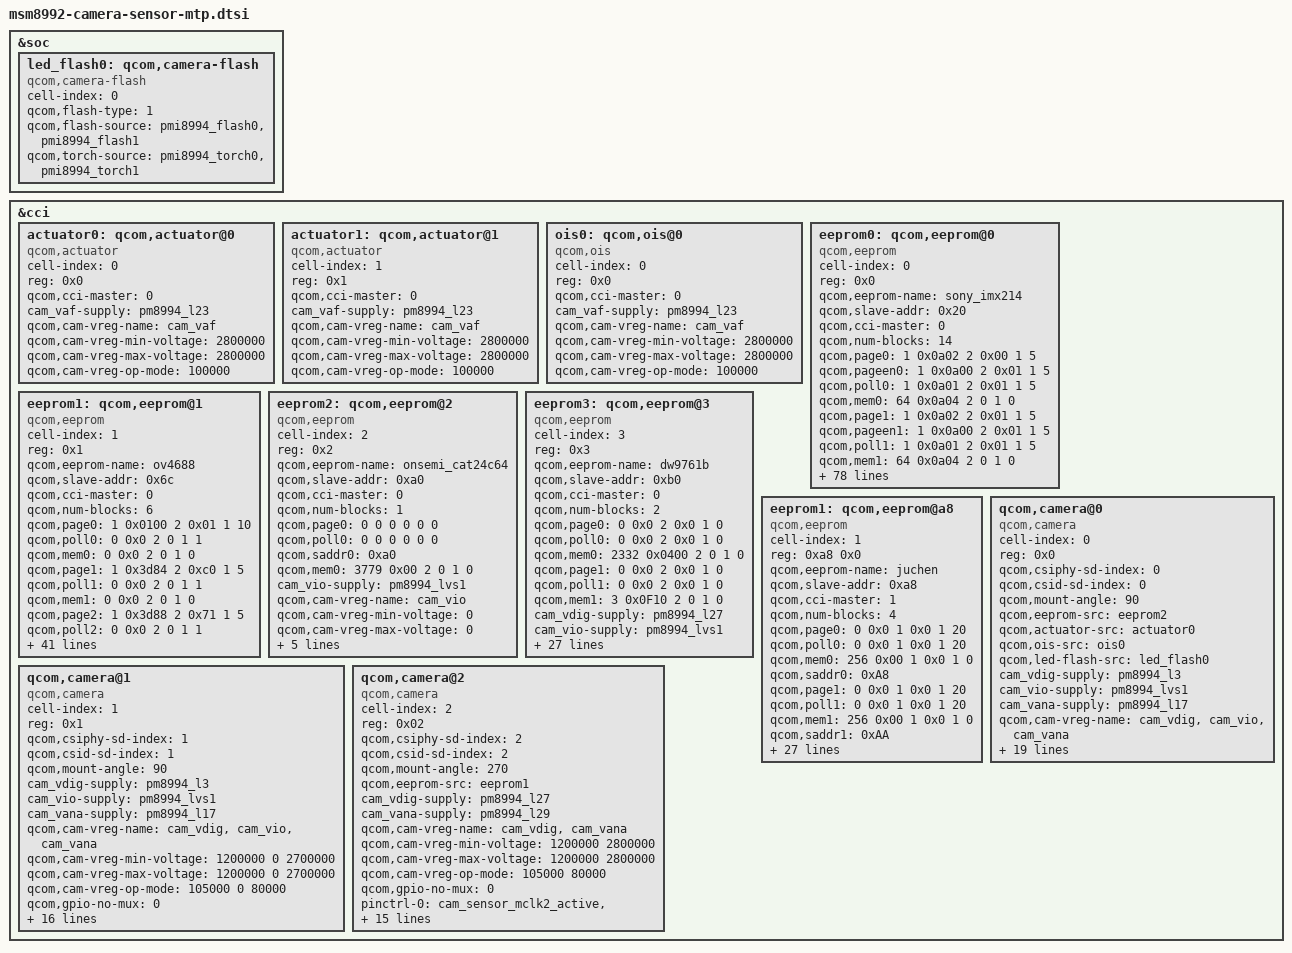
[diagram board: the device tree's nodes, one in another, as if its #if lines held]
/*
 * Copyright (c) 2014-2016, The Linux Foundation. All rights reserved.
 *
 * This program is free software; you can redistribute it and/or modify
 * it under the terms of the GNU General Public License version 2 and
 * only version 2 as published by the Free Software Foundation.
 *
 * This program is distributed in the hope that it will be useful,
 * but WITHOUT ANY WARRANTY; without even the implied warranty of
 * MERCHANTABILITY or FITNESS FOR A PARTICULAR PURPOSE.  See the
 * GNU General Public License for more details.
 */

&soc {
	led_flash0: qcom,camera-flash {
		cell-index = <0>;
		compatible = "qcom,camera-flash";
		qcom,flash-type = <1>;
		qcom,flash-source = <&pmi8994_flash0 &pmi8994_flash1>;
		qcom,torch-source = <&pmi8994_torch0 &pmi8994_torch1>;
	};
};

&cci {
	actuator0: qcom,actuator@0 {
		cell-index = <0>;
		reg = <0x0>;
		compatible = "qcom,actuator";
		qcom,cci-master = <0>;
		cam_vaf-supply = <&pm8994_l23>;
		qcom,cam-vreg-name = "cam_vaf";
		qcom,cam-vreg-min-voltage = <2800000>;
		qcom,cam-vreg-max-voltage = <2800000>;
		qcom,cam-vreg-op-mode = <100000>;
	};

#ifndef CONFIG_VENDOR_EDIT
	actuator1: qcom,actuator@1 {
		cell-index = <1>;
		reg = <0x1>;
		compatible = "qcom,actuator";
		qcom,cci-master = <0>;
		cam_vaf-supply = <&pm8994_l23>;
		qcom,cam-vreg-name = "cam_vaf";
		qcom,cam-vreg-min-voltage = <2800000>;
		qcom,cam-vreg-max-voltage = <2800000>;
		qcom,cam-vreg-op-mode = <100000>;
	};


	ois0: qcom,ois@0 {
		cell-index = <0>;
		reg = <0x0>;
		compatible = "qcom,ois";
		qcom,cci-master = <0>;
		cam_vaf-supply = <&pm8994_l23>;
		qcom,cam-vreg-name = "cam_vaf";
		qcom,cam-vreg-min-voltage = <2800000>;
		qcom,cam-vreg-max-voltage = <2800000>;
		qcom,cam-vreg-op-mode = <100000>;
	};

	eeprom0: qcom,eeprom@0 {
		cell-index = <0>;
		reg = <0x0>;
		qcom,eeprom-name = "sony_imx214";
		compatible = "qcom,eeprom";
		qcom,slave-addr = <0x20>;
		qcom,cci-master = <0>;
		qcom,num-blocks = <14>;
		qcom,page0 = <1 0x0a02 2 0x00 1 5>;
		qcom,pageen0 = <1 0x0a00 2 0x01 1 5>;
		qcom,poll0 = <1 0x0a01 2 0x01 1 5>;
		qcom,mem0 = <64 0x0a04 2 0 1 0>;

		qcom,page1 = <1 0x0a02 2 0x01 1 5>;
		qcom,pageen1 = <1 0x0a00 2 0x01 1 5>;
		qcom,poll1 = <1 0x0a01 2 0x01 1 5>;
		qcom,mem1 = <64 0x0a04 2 0 1 0>;

		qcom,page2 = <1 0x0a02 2 0x02 1 5>;
		qcom,pageen2 = <1 0x0a00 2 0x01 1 5>;
		qcom,poll2 = <1 0x0a01 2 0x01 1 5>;
		qcom,mem2 = <64 0x0a04 2 0 1 0>;

		qcom,page3 = <1 0x0a02 2 0x03 1 5>;
		qcom,pageen3 = <1 0x0a00 2 0x01 1 5>;
		qcom,poll3 = <1 0x0a01 2 0x01 1 5>;
		qcom,mem3 = <64 0x0a04 2 0 1 0>;

		qcom,page4 = <1 0x0a02 2 0x04 1 5>;
		qcom,pageen4 = <1 0x0a00 2 0x01 1 5>;
		qcom,poll4 = <1 0x0a01 2 0x01 1 5>;
		qcom,mem4 = <64 0x0a04 2 0 1 0>;

		qcom,page5 = <1 0x0a02 2 0x05 1 5>;
		qcom,pageen5 = <1 0x0a00 2 0x01 1 5>;
		qcom,poll5 = <1 0x0a01 2 0x01 1 5>;
		qcom,mem5 = <64 0x0a04 2 0 1 0>;

		qcom,page6 = <1 0x0a02 2 0x06 1 5>;
		qcom,pageen6 = <1 0x0a00 2 0x01 1 5>;
		qcom,poll6 = <1 0x0a01 2 0x01 1 5>;
		qcom,mem6 = <64 0x0a04 2 0 1 0>;

		qcom,page7 = <1 0x0a02 2 0x07 1 5>;
		qcom,pageen7 = <1 0x0a00 2 0x01 1 5>;
		qcom,poll7 = <1 0x0a01 2 0x01 1 5>;
		qcom,mem7 = <64 0x0a04 2 0 1 0>;

		qcom,page8 = <1 0x0a02 2 0x08 1 5>;
		qcom,pageen8 = <1 0x0a00 2 0x01 1 5>;
		qcom,poll8 = <1 0x0a01 2 0x01 1 5>;
		qcom,mem8 = <64 0x0a04 2 0 1 0>;

		qcom,page9 = <1 0x0a02 2 0x09 1 5>;
		qcom,pageen9 = <1 0x0a00 2 0x01 1 5>;
		qcom,poll9 = <1 0x0a01 2 0x01 1 5>;
		qcom,mem9 = <64 0x0a04 2 0 1 0>;

		qcom,page10 = <1 0x0a02 2 0x0A 1 5>;
		qcom,pageen10 = <1 0x0a00 2 0x01 1 5>;
		qcom,poll10 = <1 0x0a01 2 0x01 1 5>;
		qcom,mem10 = <64 0x0a04 2 0 1 0>;

		qcom,page11 = <1 0x0a02 2 0x0B 1 5>;
		qcom,pageen11 = <1 0x0a00 2 0x01 1 5>;
		qcom,poll11 = <1 0x0a01 2 0x01 1 5>;
		qcom,mem11 = <64 0x0a04 2 0 1 0>;

		qcom,page12 = <1 0x0a02 2 0x0C 1 5>;
		qcom,pageen12 = <1 0x0a00 2 0x01 1 5>;
		qcom,poll12 = <1 0x0a01 2 0x01 1 5>;
		qcom,mem12 = <64 0x0a04 2 0 1 0>;

		qcom,page13 = <1 0x0a02 2 0x0D 1 5>;
		qcom,pageen13 = <1 0x0a00 2 0x01 1 5>;
		qcom,poll13 = <1 0x0a01 2 0x01 1 5>;
		qcom,mem13 = <64 0x0a04 2 0 1 0>;

		cam_vdig-supply = <&pm8994_l27>;
		cam_vio-supply = <&pm8994_lvs1>;
		cam_vana-supply = <&pm8994_l17>;
		qcom,cam-vreg-name = "cam_vdig", "cam_vio", "cam_vana";
		qcom,cam-vreg-min-voltage = <1050000 0 2700000>;
		qcom,cam-vreg-max-voltage = <1050000 0 2700000>;
		qcom,cam-vreg-op-mode = <105000 0 80000>;
		qcom,gpio-no-mux = <0>;
		pinctrl-names = "cam_default", "cam_suspend";
		pinctrl-0 = <&cam_sensor_mclk0_active &cam_sensor_rear_active>;
		pinctrl-1 = <&cam_sensor_mclk0_suspend &cam_sensor_rear_suspend>;
		gpios = <&msm_gpio 13 0>,
			<&msm_gpio 92 0>,
			<&msm_gpio 91 0>;
		qcom,gpio-reset = <1>;
		qcom,gpio-standby = <2>;
		qcom,gpio-req-tbl-num = <0 1 2>;
		qcom,gpio-req-tbl-flags = <1 0 0>;
		qcom,gpio-req-tbl-label = "CAMIF_MCLK0",
					  "CAM_RESET0",
					  "CAM_STANDBY0";
		qcom,cam-power-seq-type = "sensor_vreg", "sensor_vreg", "sensor_vreg",
			"sensor_gpio", "sensor_gpio" , "sensor_clk";
		qcom,cam-power-seq-val = "cam_vdig", "cam_vana", "cam_vio",
			"sensor_gpio_reset", "sensor_gpio_standby","sensor_cam_mclk";
		qcom,cam-power-seq-cfg-val = <1 1 1 1 1 24000000>;
		qcom,cam-power-seq-delay = <1 1 1 30 30 5>;
		status = "ok";
		clocks = <&clock_mmss clk_mclk0_clk_src>,
				<&clock_mmss clk_camss_mclk0_clk>;
		clock-names = "cam_src_clk", "cam_clk";
	};

	eeprom1: qcom,eeprom@1 {
		cell-index = <1>;
		reg = <0x1>;
		qcom,eeprom-name = "ov4688";
		compatible = "qcom,eeprom";
		qcom,slave-addr = <0x6c>;
		qcom,cci-master = <0>;
		qcom,num-blocks = <6>;
		qcom,page0 = <1 0x0100 2 0x01 1 10>;
		qcom,poll0 = <0 0x0 2 0 1 1>;
		qcom,mem0 = <0 0x0 2 0 1 0>;

		qcom,page1 = <1 0x3d84 2 0xc0 1 5>;
		qcom,poll1 = <0 0x0 2 0 1 1>;
		qcom,mem1 = <0 0x0 2 0 1 0>;

		qcom,page2 = <1 0x3d88 2 0x71 1 5>;
		qcom,poll2 = <0 0x0 2 0 1 1>;
		qcom,mem2 = <0 0x0 2 0 1 0>;

		qcom,page3 = <1 0x3d89 2 0x10 1 5>;
		qcom,poll3 = <0 0x0 2 0 1 1>;
		qcom,mem3 = <0 0x0 2 0 1 0>;

		qcom,page4 = <1 0x3d89 2 0x71 1 5>;
		qcom,poll4 = <0 0x0 2 0 1 1>;
		qcom,mem4 = <0 0x0 2 0 1 0>;

		qcom,page5 = <1 0x3d8b 2 0x69 1 1>;
		qcom,pageen5 = <1 0x3d81 2 0x01 1 10>;
		qcom,poll5 = <0 0x0 2 0 1 1>;
		qcom,mem5 = <90 0x7110 2 0 1 0>;

		cam_vdig-supply = <&pm8994_l3>;
		cam_vio-supply = <&pm8994_lvs1>;
		cam_vana-supply = <&pm8994_l29>;
		qcom,cam-vreg-name = "cam_vdig", "cam_vio", "cam_vana";
		qcom,cam-vreg-min-voltage = <1200000 0 2800000>;
		qcom,cam-vreg-max-voltage = <1200000 0 2800000>;
		qcom,cam-vreg-op-mode = <105000 0 80000>;
		qcom,gpio-no-mux = <0>;
		pinctrl-names = "cam_default", "cam_suspend";
		pinctrl-0 = <&cam_sensor_mclk2_active &cam_sensor_front_active>;
		pinctrl-1 = <&cam_sensor_mclk2_suspend &cam_sensor_front_suspend>;
		gpios = <&msm_gpio 15 0>,
			<&msm_gpio 104 0>,
			<&msm_gpio 105 0>;
		qcom,gpio-reset = <1>;
		qcom,gpio-standby = <2>;
		qcom,gpio-req-tbl-num = <0 1 2>;
		qcom,gpio-req-tbl-flags = <1 0 0>;
		qcom,gpio-req-tbl-label = "CAMIF_MCLK2",
					  "CAM_RESET2",
					  "CAM_STANDBY2";
		qcom,cam-power-seq-type = "sensor_vreg", "sensor_vreg", "sensor_vreg",
			"sensor_gpio", "sensor_gpio" , "sensor_clk";
		qcom,cam-power-seq-val = "cam_vdig", "cam_vana", "cam_vio",
			"sensor_gpio_reset", "sensor_gpio_standby","sensor_cam_mclk";
		qcom,cam-power-seq-cfg-val = <1 1 1 1 1 24000000>;
		qcom,cam-power-seq-delay = <1 1 1 30 30 5>;
		status = "ok";
		clocks = <&clock_mmss clk_mclk2_clk_src>,
				<&clock_mmss clk_camss_mclk2_clk>;
		clock-names = "cam_src_clk", "cam_clk";
	};
#endif

	eeprom2: qcom,eeprom@2 {
		cell-index = <2>;
		reg = <0x2>;
#ifdef CONFIG_VENDOR_EDIT
		qcom,eeprom-name = "onsemi_cat24c64";
#else
		qcom,eeprom-name = "onsemi_cat24c32";
#endif
		compatible = "qcom,eeprom";
		qcom,slave-addr = <0xa0>;
		qcom,cci-master = <0>;
		qcom,num-blocks = <1>;
		qcom,page0 = <0 0 0 0 0 0>;
		qcom,poll0 = <0 0 0 0 0 0>;
		qcom,saddr0 = <0xa0>;
#ifdef CONFIG_VENDOR_EDIT
		qcom,mem0 = <3779 0x00 2 0 1 0>;
#else
		qcom,mem0 = <2245 0x00 2 0 1 0>;
#endif

		cam_vio-supply = <&pm8994_lvs1>;
		qcom,cam-vreg-name = "cam_vio";
		qcom,cam-vreg-min-voltage = <0>;
		qcom,cam-vreg-max-voltage = <0>;
		qcom,cam-vreg-op-mode = <0>;
#ifndef CONFIG_VENDOR_EDIT
		qcom,cam-power-seq-type = "sensor_vreg";
		qcom,cam-power-seq-val = "cam_vio";
		qcom,cam-power-seq-cfg-val = <1>;
		qcom,cam-power-seq-delay = <1>;
		status = "ok";
	};

	eeprom3: qcom,eeprom@3 {
		cell-index = <3>;
		reg = <0x3>;
		qcom,eeprom-name = "dw9761b";
		compatible = "qcom,eeprom";
		qcom,slave-addr = <0xb0>;
		qcom,cci-master = <0>;
		qcom,num-blocks = <2>;

		qcom,page0 = <0 0x0 2 0x0 1 0>;
		qcom,poll0 = <0 0x0 2 0x0 1 0>;
		qcom,mem0 = <2332 0x0400 2 0 1 0>;

		qcom,page1 = <0 0x0 2 0x0 1 0>;
		qcom,poll1 = <0 0x0 2 0x0 1 0>;
		qcom,mem1 = <3 0x0F10 2 0 1 0>;

		cam_vdig-supply = <&pm8994_l27>;
		cam_vio-supply = <&pm8994_lvs1>;
		cam_vana-supply = <&pm8994_l17>;
		cam_vaf-supply = <&pm8994_l23>;
		qcom,cam-vreg-name = "cam_vdig", "cam_vio", "cam_vana", "cam_vaf";
		qcom,cam-vreg-min-voltage = <1050000 0 2700000 2800000>;
		qcom,cam-vreg-max-voltage = <1050000 0 2700000 2800000>;
		qcom,cam-vreg-op-mode = <105000 0 80000 100000>;
#endif
		qcom,gpio-no-mux = <0>;
		pinctrl-names = "cam_default", "cam_suspend";
		pinctrl-0 = <&cam_sensor_mclk0_active &cam_sensor_rear_active>;
		pinctrl-1 = <&cam_sensor_mclk0_suspend &cam_sensor_rear_suspend>;
		gpios = <&msm_gpio 13 0>,
#ifdef CONFIG_VENDOR_EDIT
			<&msm_gpio 92 0>;
		qcom,gpio-reset = <1>;
		qcom,gpio-req-tbl-num = <0 1>;
		qcom,gpio-req-tbl-flags = <1 0>;
		qcom,gpio-req-tbl-label = "CAMIF_MCLK0",
					  "CAM_RESET0";

         	qcom,i2c-freq-mode = <1>;
		qcom,cam-power-seq-type = "sensor_vreg";
		qcom,cam-power-seq-val = "cam_vio";
		qcom,cam-power-seq-cfg-val = <1>;
		qcom,cam-power-seq-delay = <1>;
#else
			<&msm_gpio 92 0>,
			<&msm_gpio 91 0>;
		qcom,gpio-reset = <1>;
		qcom,gpio-standby = <2>;
		qcom,gpio-req-tbl-num = <0 1 2>;
		qcom,gpio-req-tbl-flags = <1 0 0>;
		qcom,gpio-req-tbl-label = "CAMIF_MCLK0",
					  "CAM_RESET0",
					  "CAM_STANDBY0";
		qcom,cam-power-seq-type = "sensor_vreg", "sensor_vreg",
			"sensor_vreg", "sensor_vreg", "sensor_gpio",
			"sensor_gpio" ,"sensor_clk";
		qcom,cam-power-seq-val = "cam_vdig", "cam_vana", "cam_vio",
			"cam_vaf", "sensor_gpio_reset", "sensor_gpio_standby",
			"sensor_cam_mclk";
		qcom,cam-power-seq-cfg-val = <1 1 1 1 1 1 24000000>;
		qcom,cam-power-seq-delay = <1 1 1 1 30 30 5>;
#endif
		status = "ok";
		clocks = <&clock_mmss clk_mclk0_clk_src>,
				<&clock_mmss clk_camss_mclk0_clk>;
		clock-names = "cam_src_clk", "cam_clk";
	};

#ifdef CONFIG_VENDOR_EDIT
	eeprom1: qcom,eeprom@a8 {
		cell-index = <1>;
		reg = <0xa8 0x0>;
		qcom,eeprom-name = "juchen";
		compatible = "qcom,eeprom";
		qcom,slave-addr = <0xa8>;
		qcom,cci-master = <1>;
		qcom,num-blocks = <4>;

		qcom,page0 = <0 0x0 1 0x0 1 20>;
		qcom,poll0 = <0 0x0 1 0x0 1 20>;
		qcom,mem0 = <256 0x00 1 0x0 1 0>;
		qcom,saddr0 = <0xA8>;

		qcom,page1 = <0 0x0 1 0x0 1 20>;
		qcom,poll1 = <0 0x0 1 0x0 1 20>;
		qcom,mem1 = <256 0x00 1 0x0 1 0>;
		qcom,saddr1 = <0xAA>;


		qcom,page2 = <0 0x0 1 0x0 1 20>;
		qcom,poll2 = <0 0x0 1 0x0 1 20>;
		qcom,mem2 = <256 0x00 1 0x0 1 0>;
		qcom,saddr2 = <0xAC>;


		qcom,page3 = <0 0x0 1 0x0 1 20>;
		qcom,poll3 = <0 0x0 1 0x0 1 20>;
		qcom,mem3 = <256 0x00 1 0x0 1 0>;
		qcom,saddr3 = <0xAE>;

		qcom,cam-vreg-name = "cam_vdig","cam_vana";
		qcom,cam-vreg-min-voltage = <1200000 2800000>;
		qcom,cam-vreg-max-voltage = <1200000 2800000>;
		qcom,cam-vreg-op-mode = <105000 80000>;

		qcom,gpio-no-mux = <0>;
		pinctrl-names = "cam_default", "cam_suspend";
		pinctrl-0 = <&cam_sensor_mclk2_active &cam_sensor_front_active>;
		pinctrl-1 = <&cam_sensor_mclk2_suspend &cam_sensor_front_suspend>;
		gpios = <&msm_gpio 93 0>; //"CAM_VIO"
	
		qcom,gpio-vio = <0>;
		qcom,gpio-req-tbl-num = <0 >;
		qcom,gpio-req-tbl-flags = <0 >;
		qcom,gpio-req-tbl-label = "CAM_VIO";
         qcom,i2c-freq-mode = <1>;
		qcom,cam-power-seq-type = "sensor_gpio";
		qcom,cam-power-seq-val = "sensor_gpio_vio";
		qcom,cam-power-seq-cfg-val = <1>;
		qcom,cam-power-seq-delay = <2>;
	};
#else
	eeprom4: qcom,eeprom@4 {
		cell-index = <4>;
		reg = <4>;
		qcom,eeprom-name = "imx258_gt24c16";
		compatible = "qcom,eeprom";
		qcom,slave-addr = <0xa0>;
		qcom,cci-master = <0>;
		qcom,num-blocks = <1>;
		qcom,page0 = <0 0 0 0 0 0>;
		qcom,poll0 = <0 0 0 0 0 0>;
		qcom,saddr0 = <0xa0>;
		qcom,mem0 = <2160 0x00 2 0 1 0>;

		cam_vio-supply = <&pm8994_lvs1>;
		qcom,cam-vreg-name = "cam_vio";
		qcom,cam-vreg-min-voltage = <0>;
		qcom,cam-vreg-max-voltage = <0>;
		qcom,cam-vreg-op-mode = <0>;
		qcom,cam-power-seq-type = "sensor_vreg";
		qcom,cam-power-seq-val = "cam_vio";
		qcom,cam-power-seq-cfg-val = <1>;
		qcom,cam-power-seq-delay = <1>;
		status = "ok";
	};
#endif

	qcom,camera@0 {
		cell-index = <0>;
		compatible = "qcom,camera";
		reg = <0x0>;
		qcom,csiphy-sd-index = <0>;
		qcom,csid-sd-index = <0>;
#ifdef CONFIG_VENDOR_EDIT
		qcom,mount-angle = <90>;
		qcom,eeprom-src = <&eeprom2>;
#else
		qcom,mount-angle = <270>;
		qcom,eeprom-src = <&eeprom0 &eeprom2 &eeprom3 &eeprom4>;
#endif
		qcom,actuator-src = <&actuator0>;
#ifndef CONFIG_VENDOR_EDIT
		qcom,ois-src = <&ois0>;
#endif
		qcom,led-flash-src = <&led_flash0>;
#ifdef CONFIG_VENDOR_EDIT
		cam_vdig-supply = <&pm8994_l3>;
#else
		cam_vdig-supply = <&pm8994_l27>;
#endif
		cam_vio-supply = <&pm8994_lvs1>;
		cam_vana-supply = <&pm8994_l17>;
		qcom,cam-vreg-name = "cam_vdig", "cam_vio", "cam_vana";
#ifdef CONFIG_VENDOR_EDIT
		qcom,cam-vreg-min-voltage = <1100000 0 2500000>;
		qcom,cam-vreg-max-voltage = <1100000 0 2500000>;
#else
		qcom,cam-vreg-min-voltage = <1050000 0 2700000>;
		qcom,cam-vreg-max-voltage = <1050000 0 2700000>;
#endif
		qcom,cam-vreg-op-mode = <105000 0 80000>;
		qcom,gpio-no-mux = <0>;
		pinctrl-names = "cam_default", "cam_suspend";
		pinctrl-0 = <&cam_sensor_mclk0_active &cam_sensor_rear_active>;
		pinctrl-1 = <&cam_sensor_mclk0_suspend &cam_sensor_rear_suspend>;
		gpios = <&msm_gpio 13 0>,
#ifdef CONFIG_VENDOR_EDIT
			<&msm_gpio 92 0>;
#else
			<&msm_gpio 92 0>,
			<&msm_gpio 91 0>;
#endif
		qcom,gpio-reset = <1>;
#ifdef CONFIG_VENDOR_EDIT
		qcom,gpio-req-tbl-num = <0 1>;
		qcom,gpio-req-tbl-flags = <1 0>;
#else
		qcom,gpio-standby = <2>;
		qcom,gpio-req-tbl-num = <0 1 2>;
		qcom,gpio-req-tbl-flags = <1 0 0>;
#endif
		qcom,gpio-req-tbl-label = "CAMIF_MCLK0",
#ifdef CONFIG_VENDOR_EDIT
					  "CAM_RESET0";
#else
					  "CAM_RESET0",
					  "CAM_STANDBY0";
#endif
		qcom,sensor-position = <0>;
		qcom,sensor-mode = <0>;
		qcom,cci-master = <0>;
		status = "ok";
		clocks = <&clock_mmss clk_mclk0_clk_src>,
				<&clock_mmss clk_camss_mclk0_clk>;
		clock-names = "cam_src_clk", "cam_clk";
	};

	qcom,camera@1 {
		cell-index = <1>;
		compatible = "qcom,camera";
		reg = <0x1>;
#ifndef CONFIG_VENDOR_EDIT
		qcom,csiphy-sd-index = <1>;
		qcom,csid-sd-index = <1>;
		qcom,mount-angle = <90>;
		cam_vdig-supply = <&pm8994_l3>;
		cam_vio-supply = <&pm8994_lvs1>;
		cam_vana-supply = <&pm8994_l17>;
		qcom,cam-vreg-name = "cam_vdig", "cam_vio", "cam_vana";
		qcom,cam-vreg-min-voltage = <1200000 0 2700000>;
		qcom,cam-vreg-max-voltage = <1200000 0 2700000>;
		qcom,cam-vreg-op-mode = <105000 0 80000>;
		qcom,gpio-no-mux = <0>;
		pinctrl-names = "cam_default", "cam_suspend";
		pinctrl-0 = <&cam_sensor_mclk1_active &cam_sensor_rear2_active>;
		pinctrl-1 = <&cam_sensor_mclk1_suspend &cam_sensor_rear2_suspend>;
		gpios = <&msm_gpio 14 0>,
			<&msm_gpio 94 0>,
			<&msm_gpio 93 0>;
		qcom,gpio-reset = <1>;
		qcom,gpio-standby = <2>;
		qcom,gpio-req-tbl-num = <0 1 2>;
		qcom,gpio-req-tbl-flags = <1 0 0>;
		qcom,gpio-req-tbl-label = "CAMIF_MCLK1",
					  "CAM_RESET1",
					  "CAM_STANDBY1";
		qcom,sensor-position = <0>;
		qcom,sensor-mode = <0>;
		qcom,cci-master = <0>;
		status = "ok";
		clocks = <&clock_mmss clk_mclk1_clk_src>,
			<&clock_mmss clk_camss_mclk1_clk>;
		clock-names = "cam_src_clk", "cam_clk";
	};

	qcom,camera@2 {
		cell-index = <2>;
		compatible = "qcom,camera";
		reg = <0x02>;
#endif
		qcom,csiphy-sd-index = <2>;
		qcom,csid-sd-index = <2>;
#ifdef CONFIG_VENDOR_EDIT
		qcom,mount-angle = <270>;
#else
		qcom,mount-angle = <90>;
#endif
		qcom,eeprom-src = <&eeprom1>;
#ifdef CONFIG_VENDOR_EDIT
		cam_vdig-supply = <&pm8994_l27>;
#else
		qcom,actuator-src = <&actuator1>;
		cam_vdig-supply = <&pm8994_l3>;
		cam_vio-supply = <&pm8994_lvs1>;
#endif
		cam_vana-supply = <&pm8994_l29>;
#ifdef CONFIG_VENDOR_EDIT
		qcom,cam-vreg-name = "cam_vdig","cam_vana";
		qcom,cam-vreg-min-voltage = <1200000 2800000>;
		qcom,cam-vreg-max-voltage = <1200000 2800000>;
		qcom,cam-vreg-op-mode = <105000 80000>;
#else
		qcom,cam-vreg-name = "cam_vdig", "cam_vio", "cam_vana";
		qcom,cam-vreg-min-voltage = <1200000 0 2800000>;
		qcom,cam-vreg-max-voltage = <1200000 0 2800000>;
		qcom,cam-vreg-op-mode = <105000 0 80000>;
#endif
		qcom,gpio-no-mux = <0>;
		pinctrl-names = "cam_default", "cam_suspend";
		pinctrl-0 = <&cam_sensor_mclk2_active &cam_sensor_front_active>;
		pinctrl-1 = <&cam_sensor_mclk2_suspend &cam_sensor_front_suspend>;
		gpios = <&msm_gpio 15 0>,
#ifdef CONFIG_VENDOR_EDIT
			<&msm_gpio 94 0>,
			<&msm_gpio 93 0>; //"CAM_VIO"
#else
			<&msm_gpio 104 0>,
			<&msm_gpio 105 0>;
#endif
		qcom,gpio-reset = <1>;
#ifdef CONFIG_VENDOR_EDIT
		qcom,gpio-vio = <2>;
#else
		qcom,gpio-standby = <2>;
#endif
		qcom,gpio-req-tbl-num = <0 1 2>;
		qcom,gpio-req-tbl-flags = <1 0 0>;
		qcom,gpio-req-tbl-label = "CAMIF_MCLK2",
					  "CAM_RESET2",
#ifdef CONFIG_VENDOR_EDIT
					  "CAM_VIO";
#else
					  "CAM_STANDBY2";
#endif
		qcom,sensor-position = <1>;
#ifdef CONFIG_VENDOR_EDIT
		qcom,sensor-mode = <1>;
		qcom,cci-master = <1>;
#else
		qcom,sensor-mode = <0>;
		qcom,cci-master = <0>;
#endif
		status = "ok";
		clocks = <&clock_mmss clk_mclk2_clk_src>,
			<&clock_mmss clk_camss_mclk2_clk>;
		clock-names = "cam_src_clk", "cam_clk";
	};
};
